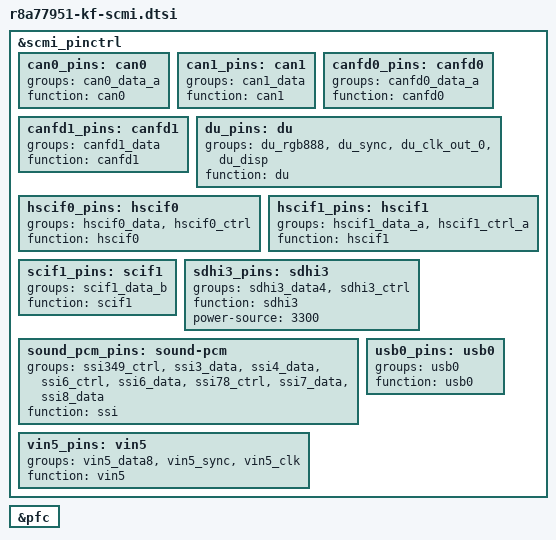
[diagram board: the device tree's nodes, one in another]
/*
 * Device Tree scmi configuration.
 *
 * Copyright (C) 2021 EPAM Systems.
 *
 * This file is licensed under the terms of the GNU General Public License
 * version 2.  This program is licensed "as is" without any warranty of any
 * kind, whether express or implied.
 */

&scmi_pinctrl {
	can0_pins: can0 {
		groups = "can0_data_a";
		function = "can0";
	};

	can1_pins: can1 {
		groups = "can1_data";
		function = "can1";
	};

	canfd0_pins: canfd0 {
		groups = "canfd0_data_a";
		function = "canfd0";
	};

	canfd1_pins: canfd1 {
		groups = "canfd1_data";
		function = "canfd1";
	};

	du_pins: du {
		groups = "du_rgb888", "du_sync", "du_clk_out_0", "du_disp";
		function = "du";
	};

	hscif0_pins: hscif0 {
		groups = "hscif0_data", "hscif0_ctrl";
		function = "hscif0";
	};

	hscif1_pins: hscif1 {
		groups = "hscif1_data_a", "hscif1_ctrl_a";
		function = "hscif1";
	};

	scif1_pins: scif1 {
		groups = "scif1_data_b";
		function = "scif1";
	};

	sdhi3_pins: sdhi3 {
		groups = "sdhi3_data4", "sdhi3_ctrl";
		function = "sdhi3";
		power-source = <3300>;
	};

	sound_pcm_pins: sound-pcm {
		groups = "ssi349_ctrl", "ssi3_data", "ssi4_data",
			 "ssi6_ctrl", "ssi6_data",
			 "ssi78_ctrl", "ssi7_data", "ssi8_data";
		function = "ssi";
	};

	usb0_pins: usb0 {
		groups = "usb0";
		function = "usb0";
	};

	vin5_pins: vin5 {
		groups = "vin5_data8", "vin5_sync", "vin5_clk";
		function = "vin5";
	};
};

&pfc {
	/delete-node/can0;
	/delete-node/can1;
	/delete-node/canfd0;
	/delete-node/canfd1;
	/delete-node/du;
	/delete-node/hscif0;
	/delete-node/hscif1;
	/delete-node/scif1;
	/delete-node/sdhi3;
	/delete-node/sound-pcm;
	/delete-node/usb0;
	/delete-node/vin5;
};
